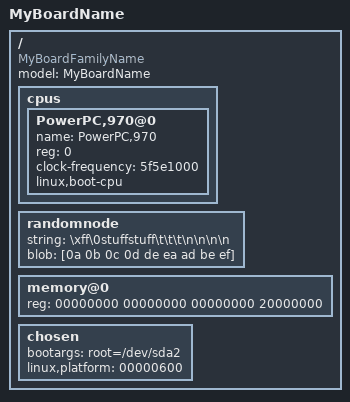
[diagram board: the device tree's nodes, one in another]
/ {
	model = "MyBoardName";
	compatible = "MyBoardFamilyName";
	#address-cells = <2>;
	#size-cells = <2>;

	cpus {
		linux,phandle = <1>;
		#address-cells = <1>;
		#size-cells = <0>;
		PowerPC,970@0 {
			name = "PowerPC,970";
			device_type = "cpu";
			reg = <0>;
			clock-frequency = <5f5e1000>;
			linux,boot-cpu;
			linux,phandle = <2>;
		};

	};

	randomnode {
		string = "\xff\0stuffstuff\t\t\t\n\n\n\n";
		blob = [0a 0b 0c 0d de ea ad be ef];
	};

	memory@0 {
		device_type = "memory";
		reg = <00000000 00000000 00000000 20000000>;
		linux,phandle = <3>;
	};

	chosen {
		bootargs = "root=/dev/sda2";
		linux,platform = <00000600>;
		linux,phandle = <4>;
	};

};
